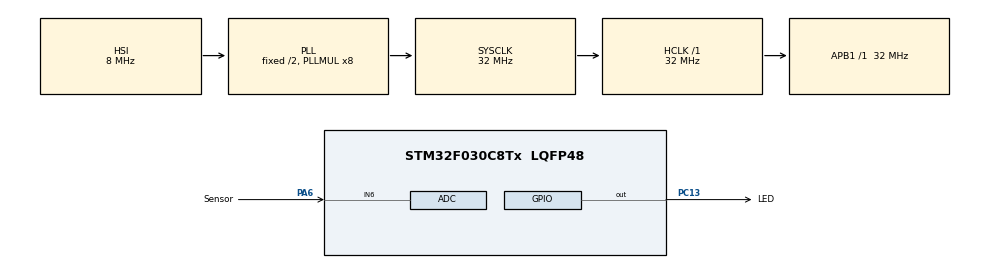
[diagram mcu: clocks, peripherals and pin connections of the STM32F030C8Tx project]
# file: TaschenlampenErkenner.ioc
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ADC.ContinuousConvMode=DISABLE
ADC.ExternalTrigConv=ADC_SOFTWARE_START
ADC.SamplingTime=ADC_SAMPLETIME_28CYCLES_5
Mcu.Family=STM32F0
Mcu.Name=STM32F030C8Tx
Mcu.Package=LQFP48
NVIC.ADC1_IRQn=true\:0\:0\:false\:false\:true\:true\:true\:true
NVIC.TIM3_IRQn=true\:0\:0\:false\:false\:true\:true\:true\:true
PA6.GPIO_Label=Sensor
PA6.Mode=IN6
PA6.Signal=ADC_IN6
PC13.GPIO_Label=LED
PC13.Signal=GPIO_Output
ProjectManager.HeapSize=0x200
ProjectManager.StackSize=0x400
ProjectManager.TargetToolchain=STM32CubeIDE
RCC.AHBFreq_Value=32000000
RCC.APB1Freq_Value=32000000
RCC.APB1TimFreq_Value=32000000
RCC.HCLKFreq_Value=32000000
RCC.PLLMUL=RCC_PLL_MUL8
RCC.SYSCLKFreq_VALUE=32000000
RCC.SYSCLKSource=RCC_SYSCLKSOURCE_PLLCLK
TIM3.Period=31
TIM3.Prescaler=99
VP_TIM3_VS_ClockSourceINT.Mode=Internal
board=custom

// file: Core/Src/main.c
/* USER CODE BEGIN Header */
/**
  ******************************************************************************
  * @file           : main.c
  * @brief          : Main program body
  ******************************************************************************
  * @attention
  *
  * Copyright (c) 2026 STMicroelectronics.
  * All rights reserved.
  *
  * This software is licensed under terms that can be found in the LICENSE file
  * in the root directory of this software component.
  * If no LICENSE file comes with this software, it is provided AS-IS.
  *
  ******************************************************************************
  */
/* USER CODE END Header */
#include "main.h"

ADC_HandleTypeDef hadc;

TIM_HandleTypeDef htim3;

void SystemClock_Config(void);
static void MX_GPIO_Init(void);
static void MX_ADC_Init(void);
static void MX_TIM3_Init(void);
/* USER CODE BEGIN PFP */

// Viele der Werte sind nicht konstant, damit man sie online anpassen kann!

// Tiefpassgefiltertes Signal
const long signal[50] = {
	-3631,
	-2849,
	-1106,
	335,
	1664,
	2821,
	3858,
	4781,
	5604,
	6360,
	7062,
	7632,
	8302,
	7944,
	6374,
	5250,
	4235,
	3361,
	2564,
	1862,
	1214,
	663,
	147,
	-351,
	-734,
	-1089,
	-1392,
	-1670,
	-1926,
	-2147,
	-2346,
	-2528,
	-2689,
	-2829,
	-2956,
	-3091,
	-3169,
	-3268,
	-3379,
	-3360,
	-3437,
	-3549,
	-3566,
	-3566,
	-3567,
	-3567,
	-3567,
	-3567,
	-3567,
	-3567
};

// Rechtecksignal beschreiben
#define periodendauer 50	// Wie viele Messzyklen eine Periode dauert
const unsigned int t_ein = 13;	// Wie viele Messzyklen das Signal an ist

#define wert_an 10000	// Wie groß der angenommene Messwert ist, wenn das Signal an ist
volatile long wert_aus = - ((float)t_ein / ((float)periodendauer - (float)t_ein)) * (float)wert_an;	// Wie groß das Signal im "Aus"-Zustand ist, um Gleichanteilsfrei zu bleiben

//#define schwelle 1000	// Der gefaltete Wert muss nachher über dieser Schwelle liegen, um als erfolgreich gemessen zu gelten
volatile long schwelle = 2000000;

// Messung
volatile long messwerte[periodendauer];	// Verlauf der Messungen
unsigned int zeiger = 0;	// Zeigt immer auf den ÄLTESTEN Messwert
volatile int my_val = 0;	// Aktueller Messwert
volatile unsigned char neuer_messwert = 0;	// bool: Neuer Messwert vorhanden, führe eine Faltung durch

volatile unsigned int erfolge_letzte_periode = 0;	// Wie viele erfolgreiche Erkennungen in der letzten Periode passiert sind

// Kumulieren über mehrere Perioden
volatile int notigeErfolgeProPeriode = 15;	// So viele Erfolge braucht es, damit die Periode als Erfolg gilt
volatile int anzahlPerioden = 50;	// Über wie viele Perioden aufgezeichnet wird
volatile int notigeErfolgreichePerioden = 10;	// Wie viele der Perioden erfolgreich sein müssen
volatile int zuletztErfolgreichePerioden;	// Wie viele bei der letzten Messung erfolgreich waren

// Erkanntes Signal
volatile unsigned char signalErkannt;	// 1, wenn alles der Meinung ist, dass das Signal vorliegt

/* USER CODE END PFP */

/* USER CODE BEGIN 0 */
void HAL_ADC_ConvCpltCallback (ADC_HandleTypeDef *hadc)
{
	// (Nachgemessen) Alle 100 us
	my_val = HAL_ADC_GetValue(hadc);
	messwerte[zeiger++] = my_val;

	if(zeiger >= periodendauer) zeiger = 0;
	neuer_messwert = 1;
}

void HAL_TIM_PeriodElapsedCallback(TIM_HandleTypeDef *htim)
{

	HAL_ADC_Start_IT(&hadc);
	//HAL_GPIO_TogglePin(LED_GPIO_Port, LED_Pin);
}

unsigned char macheFaltung(){
	// Führe eine einzelne Faltung durch und gib zurück, ob das Ergebnis über der Schwelle liegt
	long summe = 0;
	unsigned int i = zeiger;
	for (unsigned int s = 0; s < periodendauer; s++){
		summe += messwerte[i++] * signal[s];
		if (i >= periodendauer) i = 0;
	}

	return summe >= schwelle;
}

unsigned char macheFaltungRechteck(){
	// Führe eine einzelne Faltung durch und gib zurück, ob das Ergebnis über der Schwelle liegt
	long summe = 0;
	unsigned int i = zeiger;
	for (unsigned int _ = 0;_ < t_ein;_++){
		summe += messwerte[i++] * wert_an;
		if (i >= periodendauer) i = 0;
	}
	for (unsigned int _ = t_ein;_ < periodendauer;_++){
		summe += messwerte[i++] * wert_aus;
		if (i >= periodendauer) i = 0;
	}

	return summe >= schwelle;
}

/* USER CODE END 0 */

int main(void)
{

  /* MCU Configuration--------------------------------------------------------*/

  /* Reset of all peripherals, Initializes the Flash interface and the Systick. */
  HAL_Init();

  /* Configure the system clock */
  SystemClock_Config();

  /* Initialize all configured peripherals */
  MX_GPIO_Init();
  MX_ADC_Init();
  MX_TIM3_Init();
  /* USER CODE BEGIN 2 */

  //HAL_ADC_Start_IT(&hadc);
  HAL_TIM_Base_Start_IT(&htim3);

  /* USER CODE END 2 */

  /* Infinite loop */
  /* USER CODE BEGIN WHILE */
  while (1)
  {
	  // Mehrere Perioden
	  unsigned int erfolgreichePerioden = 0;

	  for(unsigned int k = 0;k < anzahlPerioden;k++){

		  // Einzelne Periode
		  unsigned int erfolge = 0;

		  for(unsigned int i = 0;i < periodendauer; i++){
			  while (!neuer_messwert);	// Warte auf Messwert
			  neuer_messwert = 0;

			  erfolge += macheFaltung();
		  }
		  erfolge_letzte_periode = erfolge;
		  erfolgreichePerioden += erfolge > notigeErfolgeProPeriode;
	  }

	  signalErkannt = erfolgreichePerioden >= notigeErfolgreichePerioden;
	  HAL_GPIO_WritePin(LED_GPIO_Port, LED_Pin, signalErkannt);
	  zuletztErfolgreichePerioden = erfolgreichePerioden;
	  //HAL_GPIO_TogglePin(LED_GPIO_Port, LED_Pin);
	  //HAL_Delay(500);
    /* USER CODE END WHILE */

  }
}

void SystemClock_Config(void)
{
  RCC_OscInitTypeDef RCC_OscInitStruct = {0};
  RCC_ClkInitTypeDef RCC_ClkInitStruct = {0};

  /** Initializes the RCC Oscillators according to the specified parameters
  * in the RCC_OscInitTypeDef structure.
  */
  RCC_OscInitStruct.OscillatorType = RCC_OSCILLATORTYPE_HSI|RCC_OSCILLATORTYPE_HSI14;
  RCC_OscInitStruct.HSIState = RCC_HSI_ON;
  RCC_OscInitStruct.HSI14State = RCC_HSI14_ON;
  RCC_OscInitStruct.HSICalibrationValue = RCC_HSICALIBRATION_DEFAULT;
  RCC_OscInitStruct.HSI14CalibrationValue = 16;
  RCC_OscInitStruct.PLL.PLLState = RCC_PLL_ON;
  RCC_OscInitStruct.PLL.PLLSource = RCC_PLLSOURCE_HSI;
  RCC_OscInitStruct.PLL.PLLMUL = RCC_PLL_MUL8;
  RCC_OscInitStruct.PLL.PREDIV = RCC_PREDIV_DIV1;
  if (HAL_RCC_OscConfig(&RCC_OscInitStruct) != HAL_OK)
  {
    Error_Handler();
  }

  /** Initializes the CPU, AHB and APB buses clocks
  */
  RCC_ClkInitStruct.ClockType = RCC_CLOCKTYPE_HCLK|RCC_CLOCKTYPE_SYSCLK
                              |RCC_CLOCKTYPE_PCLK1;
  RCC_ClkInitStruct.SYSCLKSource = RCC_SYSCLKSOURCE_PLLCLK;
  RCC_ClkInitStruct.AHBCLKDivider = RCC_SYSCLK_DIV1;
  RCC_ClkInitStruct.APB1CLKDivider = RCC_HCLK_DIV1;

  if (HAL_RCC_ClockConfig(&RCC_ClkInitStruct, FLASH_LATENCY_1) != HAL_OK)
  {
    Error_Handler();
  }
}

static void MX_ADC_Init(void)
{

  ADC_ChannelConfTypeDef sConfig = {0};

  /** Configure the global features of the ADC (Clock, Resolution, Data Alignment and number of conversion)
  */
  hadc.Instance = ADC1;
  hadc.Init.ClockPrescaler = ADC_CLOCK_ASYNC_DIV1;
  hadc.Init.Resolution = ADC_RESOLUTION_12B;
  hadc.Init.DataAlign = ADC_DATAALIGN_RIGHT;
  hadc.Init.ScanConvMode = ADC_SCAN_DIRECTION_FORWARD;
  hadc.Init.EOCSelection = ADC_EOC_SINGLE_CONV;
  hadc.Init.LowPowerAutoWait = DISABLE;
  hadc.Init.LowPowerAutoPowerOff = DISABLE;
  hadc.Init.ContinuousConvMode = DISABLE;
  hadc.Init.DiscontinuousConvMode = DISABLE;
  hadc.Init.ExternalTrigConv = ADC_SOFTWARE_START;
  hadc.Init.ExternalTrigConvEdge = ADC_EXTERNALTRIGCONVEDGE_NONE;
  hadc.Init.DMAContinuousRequests = DISABLE;
  hadc.Init.Overrun = ADC_OVR_DATA_PRESERVED;
  if (HAL_ADC_Init(&hadc) != HAL_OK)
  {
    Error_Handler();
  }

  /** Configure for the selected ADC regular channel to be converted.
  */
  sConfig.Channel = ADC_CHANNEL_6;
  sConfig.Rank = ADC_RANK_CHANNEL_NUMBER;
  sConfig.SamplingTime = ADC_SAMPLETIME_28CYCLES_5;
  if (HAL_ADC_ConfigChannel(&hadc, &sConfig) != HAL_OK)
  {
    Error_Handler();
  }

}

static void MX_TIM3_Init(void)
{

  TIM_ClockConfigTypeDef sClockSourceConfig = {0};
  TIM_MasterConfigTypeDef sMasterConfig = {0};

  htim3.Instance = TIM3;
  htim3.Init.Prescaler = 99;
  htim3.Init.CounterMode = TIM_COUNTERMODE_UP;
  htim3.Init.Period = 31;
  htim3.Init.ClockDivision = TIM_CLOCKDIVISION_DIV1;
  htim3.Init.AutoReloadPreload = TIM_AUTORELOAD_PRELOAD_DISABLE;
  if (HAL_TIM_Base_Init(&htim3) != HAL_OK)
  {
    Error_Handler();
  }
  sClockSourceConfig.ClockSource = TIM_CLOCKSOURCE_INTERNAL;
  if (HAL_TIM_ConfigClockSource(&htim3, &sClockSourceConfig) != HAL_OK)
  {
    Error_Handler();
  }
  sMasterConfig.MasterOutputTrigger = TIM_TRGO_RESET;
  sMasterConfig.MasterSlaveMode = TIM_MASTERSLAVEMODE_DISABLE;
  if (HAL_TIMEx_MasterConfigSynchronization(&htim3, &sMasterConfig) != HAL_OK)
  {
    Error_Handler();
  }

}

static void MX_GPIO_Init(void)
{
  GPIO_InitTypeDef GPIO_InitStruct = {0};

  /* GPIO Ports Clock Enable */
  __HAL_RCC_GPIOC_CLK_ENABLE();
  __HAL_RCC_GPIOA_CLK_ENABLE();

  /*Configure GPIO pin Output Level */
  HAL_GPIO_WritePin(LED_GPIO_Port, LED_Pin, GPIO_PIN_RESET);

  /*Configure GPIO pin : LED_Pin */
  GPIO_InitStruct.Pin = LED_Pin;
  GPIO_InitStruct.Mode = GPIO_MODE_OUTPUT_PP;
  GPIO_InitStruct.Pull = GPIO_NOPULL;
  GPIO_InitStruct.Speed = GPIO_SPEED_FREQ_LOW;
  HAL_GPIO_Init(LED_GPIO_Port, &GPIO_InitStruct);

}

void Error_Handler(void)
{
  __disable_irq();
  while (1)
  {
  }
}
